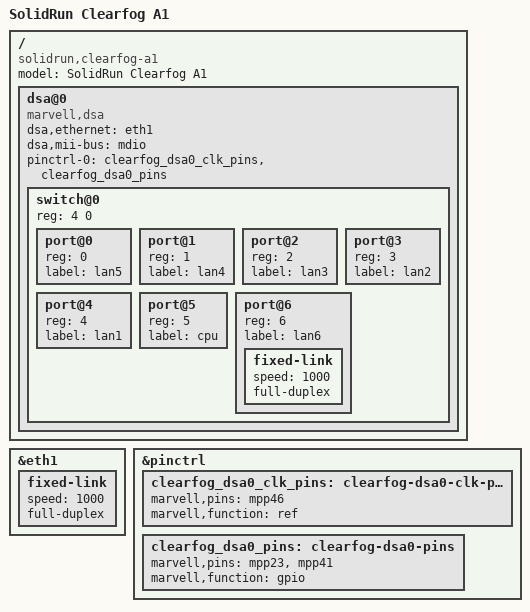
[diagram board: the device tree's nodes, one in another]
/*
 * Device Tree file for SolidRun Clearfog Pro revision A1 rev 2.0 (88F6828)
 *
 *  Copyright (C) 2015 Russell King
 *
 * This board is in development; the contents of this file work with
 * the A1 rev 2.0 of the board, which does not represent final
 * production board.  Things will change, don't expect this file to
 * remain compatible info the future.
 *
 * This file is dual-licensed: you can use it either under the terms
 * of the GPL or the X11 license, at your option. Note that this dual
 * licensing only applies to this file, and not this project as a
 * whole.
 *
 *  a) This file is free software; you can redistribute it and/or
 *     modify it under the terms of the GNU General Public License
 *     version 2 as published by the Free Software Foundation.
 *
 *     This file is distributed in the hope that it will be useful,
 *     but WITHOUT ANY WARRANTY; without even the implied warranty of
 *     MERCHANTABILITY or FITNESS FOR A PARTICULAR PURPOSE.  See the
 *     GNU General Public License for more details.
 *
 * Or, alternatively,
 *
 *  b) Permission is hereby granted, free of charge, to any person
 *     obtaining a copy of this software and associated documentation
 *     files (the "Software"), to deal in the Software without
 *     restriction, including without limitation the rights to use,
 *     copy, modify, merge, publish, distribute, sublicense, and/or
 *     sell copies of the Software, and to permit persons to whom the
 *     Software is furnished to do so, subject to the following
 *     conditions:
 *
 *     The above copyright notice and this permission notice shall be
 *     included in all copies or substantial portions of the Software.
 *
 *     THE SOFTWARE IS PROVIDED "AS IS", WITHOUT WARRANTY OF ANY KIND,
 *     EXPRESS OR IMPLIED, INCLUDING BUT NOT LIMITED TO THE WARRANTIES
 *     OF MERCHANTABILITY, FITNESS FOR A PARTICULAR PURPOSE AND
 *     NONINFRINGEMENT. IN NO EVENT SHALL THE AUTHORS OR COPYRIGHT
 *     HOLDERS BE LIABLE FOR ANY CLAIM, DAMAGES OR OTHER LIABILITY,
 *     WHETHER IN AN ACTION OF CONTRACT, TORT OR OTHERWISE, ARISING
 *     FROM, OUT OF OR IN CONNECTION WITH THE SOFTWARE OR THE USE OR
 *     OTHER DEALINGS IN THE SOFTWARE.
 */

/dts-v1/;
#include "armada-388-clearfog.dtsi"

/ {
	model = "SolidRun Clearfog A1";
	compatible = "solidrun,clearfog-a1", "marvell,armada388",
		"marvell,armada385", "marvell,armada380";

	dsa@0 {
		compatible = "marvell,dsa";
		dsa,ethernet = <&eth1>;
		dsa,mii-bus = <&mdio>;
		pinctrl-0 = <&clearfog_dsa0_clk_pins &clearfog_dsa0_pins>;
		pinctrl-names = "default";
		#address-cells = <2>;
		#size-cells = <0>;

		switch@0 {
			#address-cells = <1>;
			#size-cells = <0>;
			reg = <4 0>;

			port@0 {
				reg = <0>;
				label = "lan5";
			};

			port@1 {
				reg = <1>;
				label = "lan4";
			};

			port@2 {
				reg = <2>;
				label = "lan3";
			};

			port@3 {
				reg = <3>;
				label = "lan2";
			};

			port@4 {
				reg = <4>;
				label = "lan1";
			};

			port@5 {
				reg = <5>;
				label = "cpu";
			};

			port@6 {
				/* 88E1512 external phy */
				reg = <6>;
				label = "lan6";
				fixed-link {
					speed = <1000>;
					full-duplex;
				};
			};
		};
	};
};

&eth1 {
	/* ethernet@30000 */
	fixed-link {
		speed = <1000>;
		full-duplex;
	};
};

&pinctrl {
	clearfog_dsa0_clk_pins: clearfog-dsa0-clk-pins {
		marvell,pins = "mpp46";
		marvell,function = "ref";
	};
	clearfog_dsa0_pins: clearfog-dsa0-pins {
		marvell,pins = "mpp23", "mpp41";
		marvell,function = "gpio";
	};
};
